# MSP430G2X11 register map
Vendor: msp430gen; File version: v0.4.0-16-g4f822b9
Registers are 8-bit, read-write, reset 0x0 unless marked. A register's access mark holds for its fields unless they carry their own. Offsets are from the block's base; [hi:lo] are bit positions; 'fields as' and 'values as' point back to an identical list.

## COMPARATOR_A
Base 0x00000058
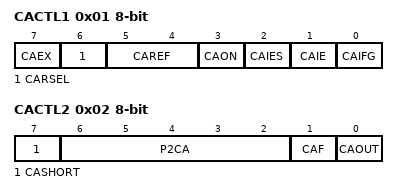
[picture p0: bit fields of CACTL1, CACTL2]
0x01 CACTL1 — Comparator A Control 1
  [7] CAEX — Comp. A Exchange Inputs
  [6] CARSEL — Comp. A Internal Reference Enable
  [5:4] CAREF — Comp. A Internal Reference Select 0
    0=Comp. A Int. Ref. Select 0 : Off; 1=Comp. A Int. Ref. Select 1 : 0.25*Vcc; 2=Comp. A Int. Ref. Select 2 : 0.5*Vcc; 3=Comp. A Int. Ref. Select 3 : Vt
  [3] CAON — Comp. A enable
  [2] CAIES — Comp. A Int. Edge Select: 0:rising / 1:falling
  [1] CAIE — Comp. A Interrupt Enable
  [0] CAIFG — Comp. A Interrupt Flag
0x02 CACTL2 — Comparator A Control 2
  [7] CASHORT — Comp. A Short + and - Terminals
  [6:2] P2CA — Comp. A +Terminal Multiplexer
    0=NONE_NONE (No + or - connection); 1=CA0_NONE (Connect + to CA0, no connection to -); 2=NONE_CA1 (No connection to +, connect - to CA1); 3=CA0_CA1 (Connect + to CA0, connect - to CA1); 4=NONE_CA2 (No connection to +, connect - to CA2); 5=CA0_CA2 (Connect + to CA0, connect - to CA2); 6=NONE_CA3 (No connection to +, connect - to CA3); 7=CA0_CA3 (Connect + to CA0, connect - to CA3); 8=NONE_CA4 (No connection to +, connect - to CA4); 9=CA0_CA4 (Connect + to CA0, connect - to CA4); 10=NONE_CA5 (No connection to +, connect - to CA5); 11=CA0_CA5 (Connect + to CA0, connect - to CA5); 12=NONE_CA6 (No connection to +, connect - to CA6); 13=CA0_CA6 (Connect + to CA0, connect - to CA6); 14=NONE_CA7 (No connection to +, connect - to CA7); 15=CA0_CA7 (Connect + to CA0, connect - to CA7); 16=CA1_NONE (Connect + to CA1, no connection to -); 17=CA2_NONE (Connect + to CA2, no connection to -); 18=CA1_CA1 (Connect + to CA1, connect - to CA1); 19=CA2_CA1 (Connect + to CA2, connect - to CA1); 20=CA1_CA2 (Connect + to CA1, connect - to CA2); 21=CA2_CA2 (Connect + to CA2, connect - to CA2); 22=CA1_CA3 (Connect + to CA1, connect - to CA3); 23=CA2_CA3 (Connect + to CA2, connect - to CA3); 24=CA1_CA4 (Connect + to CA1, connect - to CA4); 25=CA2_CA4 (Connect + to CA2, connect - to CA4); 26=CA1_CA5 (Connect + to CA1, connect - to CA5); 27=CA2_CA5 (Connect + to CA2, connect - to CA5); 28=CA1_CA6 (Connect + to CA1, connect - to CA6); 29=CA2_CA6 (Connect + to CA2, connect - to CA6); 30=CA1_CA7 (Connect + to CA1, connect - to CA7); 31=CA2_CA7 (Connect + to CA2, connect - to CA7)
  [1] CAF — Comp. A Enable Output Filter
  [0] CAOUT — Comp. A Output
0x03 CAPD — Comparator A Port Disable
  [7] CAPD7 — Comp. A Disable Input Buffer of Port Register .7
  [6] CAPD6 — Comp. A Disable Input Buffer of Port Register .6
  [5] CAPD5 — Comp. A Disable Input Buffer of Port Register .5
  [4] CAPD4 — Comp. A Disable Input Buffer of Port Register .4
  [3] CAPD3 — Comp. A Disable Input Buffer of Port Register .3
  [2] CAPD2 — Comp. A Disable Input Buffer of Port Register .2
  [1] CAPD1 — Comp. A Disable Input Buffer of Port Register .1
  [0] CAPD0 — Comp. A Disable Input Buffer of Port Register .0
  [7:0] CAPD — Comparator A Port Disable register

## CALIBRATION_DATA
Base 0x000010FE
0x00 CALDCO_1MHZ — DCOCTL Calibration Data for 1MHz
  [7:0] CALDCO_1MHZ — DCOCTL Calibration Data register
0x01 CALBC1_1MHZ — BCSCTL1 Calibration Data for 1MHz
  [7:0] CALBC1_1MHZ — BCSCTL1 Calibration Data register

## WATCHDOG_TIMER
Base 0x00000120
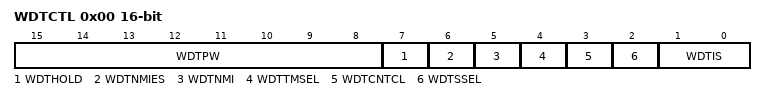
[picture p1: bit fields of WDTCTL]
0x00 WDTCTL 16-bit — Watchdog Timer Control
  [15:8] WDTPW — Watchdog Timer Password
    on read: 105=PASSWORD (Value always read from the Watchdog Password register) | on write: 90=PASSWORD (Value which must be written to the Watchdog Password register)
  [7] WDTHOLD
  [6] WDTNMIES
  [5] WDTNMI
  [4] WDTTMSEL
  [3] WDTCNTCL
  [2] WDTSSEL
  [1:0] WDTIS — WDTIS0

## FLASH
Base 0x00000128
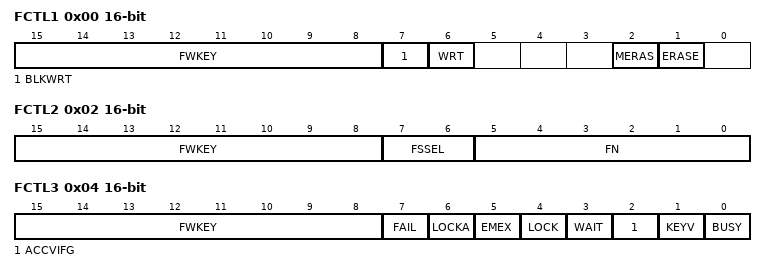
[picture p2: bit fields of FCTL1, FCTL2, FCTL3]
0x00 FCTL1 16-bit — FLASH Control 1
  [15:8] FWKEY — FCTL1 Password
    on read: 150=PASSWORD (Value always read from the FCTL1 Password register) | on write: 165=PASSWORD (Value which must be written to the FCTL1 Password register)
  [7] BLKWRT — Enable bit for Flash segment write
  [6] WRT — Enable bit for Flash write
  [2] MERAS — Enable bit for Flash mass erase
  [1] ERASE — Enable bit for Flash segment erase
0x02 FCTL2 16-bit — FLASH Control 2
  [15:8] FWKEY — FCTL2 Password
    on read: 150=PASSWORD (Value always read from the FCTL2 Password register) | on write: 165=PASSWORD (Value which must be written to the FCTL2 Password register)
  [7:6] FSSEL — Flash clock select 0 */ /* to distinguish from USART SSELx
    0=Flash clock select: 0 - ACLK; 1=Flash clock select: 1 - MCLK; 2=Flash clock select: 2 - SMCLK; 3=Flash clock select: 3 - SMCLK
  [5:0] FN — Divide Flash clock by 1 to 64 using FN0 to FN5 according to:
0x04 FCTL3 16-bit — FLASH Control 3
  [15:8] FWKEY — FCTL3 Password
    on read: 150=PASSWORD (Value always read from the FCTL3 Password register) | on write: 165=PASSWORD (Value which must be written to the FCTL3 Password register)
  [7] FAIL — Last Program or Erase failed
  [6] LOCKA — Segment A Lock bit: read = 1 - Segment is locked (read only)
  [5] EMEX — Flash Emergency Exit
  [4] LOCK — Lock bit: 1 - Flash is locked (read only)
  [3] WAIT — Wait flag for segment write
  [2] ACCVIFG — Flash Access violation flag
  [1] KEYV — Flash Key violation flag
  [0] BUSY — Flash busy: 1

## TIMER_A2
Base 0x0000012E
0x00 TAIV 16-bit — Timer A Interrupt Vector Word
  [3:0] TAIV — Timer A Interrupt Vector value
    0=NONE (No interrupt pending); 2=TACCR1 (Capture/Compare 1); 10=TAIFG (Timer overflow)
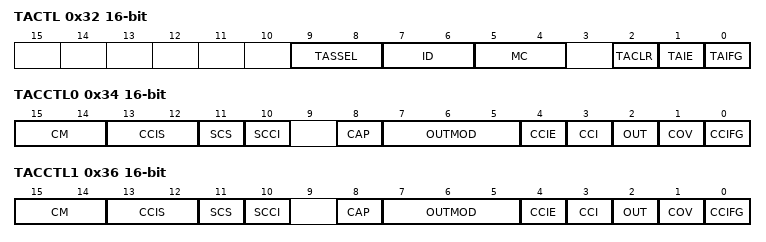
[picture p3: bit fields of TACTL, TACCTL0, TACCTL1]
0x32 TACTL 16-bit — Timer A Control
  [9:8] TASSEL — Timer A clock source select 1
    0=Timer A clock source select: 0 - TACLK; 1=Timer A clock source select: 1 - ACLK; 2=Timer A clock source select: 2 - SMCLK; 3=Timer A clock source select: 3 - INCLK
  [7:6] ID — Timer A clock input divider 1
    0=Timer A input divider: 0 - /1; 1=Timer A input divider: 1 - /2; 2=Timer A input divider: 2 - /4; 3=Timer A input divider: 3 - /8
  [5:4] MC — Timer A mode control 1
    0=Timer A mode control: 0 - Stop; 1=Timer A mode control: 1 - Up to CCR0; 2=Timer A mode control: 2 - Continous up; 3=Timer A mode control: 3 - Up/Down
  [2] TACLR — Timer A counter clear
  [1] TAIE — Timer A counter interrupt enable
  [0] TAIFG — Timer A counter interrupt flag
0x34 TACCTL0 16-bit — Timer A Capture/Compare Control 0
  [15:14] CM — Capture mode 1
    0=Capture mode: 0 - disabled; 1=Capture mode: 1 - pos. edge; 2=Capture mode: 1 - neg. edge; 3=Capture mode: 1 - both edges
  [13:12] CCIS — Capture input select 1
    0=Capture input select: 0 - CCIxA; 1=Capture input select: 1 - CCIxB; 2=Capture input select: 2 - GND; 3=Capture input select: 3 - Vcc
  [11] SCS — Capture sychronize
  [10] SCCI — Latched capture signal (read)
  [8] CAP — Capture mode: 1 /Compare mode : 0
  [7:5] OUTMOD — Output mode 2
    0=PWM output mode: 0 - output only; 1=PWM output mode: 1 - set; 2=PWM output mode: 2 - PWM toggle/reset; 3=PWM output mode: 3 - PWM set/reset; 4=PWM output mode: 4 - toggle; 5=PWM output mode: 5 - Reset; 6=PWM output mode: 6 - PWM toggle/set; 7=PWM output mode: 7 - PWM reset/set
  [4] CCIE — Capture/compare interrupt enable
  [3] CCI — Capture input signal (read)
  [2] OUT — PWM Output signal if output mode 0
  [1] COV — Capture/compare overflow flag
  [0] CCIFG — Capture/compare interrupt flag
0x36 TACCTL1 16-bit — Timer A Capture/Compare Control 1
  fields as TACCTL0
0x42 TAR 16-bit — Timer A Counter Register
0x44 TACCR0 16-bit — Timer A Capture/Compare 0
  [15:0] TACCR0 — Timer A Capture/Compare register 0
0x46 TACCR1 16-bit — Timer A Capture/Compare 1
  [15:0] TACCR1 — Timer A Capture/Compare register 1
